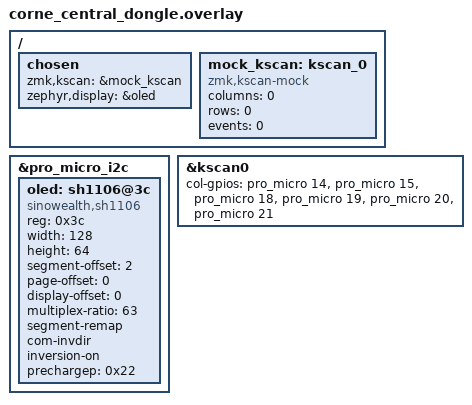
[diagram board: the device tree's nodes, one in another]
/*
 * Copyright (c) 2020 The ZMK Contributors
 *
 * SPDX-License-Identifier: MIT
 */

#include "corne.dtsi"
/ {
    chosen {
        zmk,kscan = &mock_kscan;
        zephyr,display = &oled;
    };

    mock_kscan: kscan_0 {
        compatible = "zmk,kscan-mock";
        columns = <0>;
        rows = <0>;
        events = <0>;
    };
};

&pro_micro_i2c {
    status = "okay";

    oled: sh1106@3c {
        compatible = "sinowealth,sh1106";
        reg = <0x3c>;
        width = <128>;
        height = <64>;
        segment-offset = <2>;
        page-offset = <0>;
        display-offset = <0>;
        multiplex-ratio = <63>;
        segment-remap;
        com-invdir;
        inversion-on;
        prechargep = <0x22>;
    };
};

&kscan0 {
	col-gpios
		= <&pro_micro 14 GPIO_ACTIVE_HIGH>
		, <&pro_micro 15 GPIO_ACTIVE_HIGH>
		, <&pro_micro 18 GPIO_ACTIVE_HIGH>
		, <&pro_micro 19 GPIO_ACTIVE_HIGH>
		, <&pro_micro 20 GPIO_ACTIVE_HIGH>
		, <&pro_micro 21 GPIO_ACTIVE_HIGH>
		;
};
